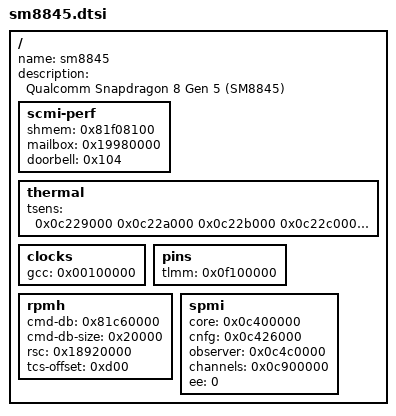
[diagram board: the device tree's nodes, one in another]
/dts-v1/;

// Shared SoC data for Snapdragon 8 Gen 5. Add register blocks with their backends.
/ {
	name = "sm8845";
	description = "Qualcomm Snapdragon 8 Gen 5 (SM8845)";

	// Channel used by the Ace 6T SM8845 reference port.
	scmi-perf {
		shmem = <0x81f08100>;
		mailbox = <0x19980000>;
		doorbell = <0x104>;
	};
	// TSENS v2, reg "tm" of tsens0..tsens6 in the Ace 6T's Android device tree (SROT at 0x0c222000..0x0c228000
	// is not needed: the hardware gives calibrated readings). Read only.
	thermal {
		tsens = <0x0c229000 0x0c22a000 0x0c22b000 0x0c22c000 0x0c22d000 0x0c22e000 0x0c22f000>;
	};

	// Ace 6T Android DT: clock-controller@100000; TLMM's per-pin registers start 1 MiB into its aperture.
	clocks {
		gcc = <0x00100000>;
	};
	pins {
		tlmm = <0x0f100000>;
	};
	// Android reserved-memory/aop_cmd_db_region and apps_rsc/ drv@2, channel@0.
	rpmh {
		cmd-db = <0x81c60000>;
		cmd-db-size = <0x20000>;
		rsc = <0x18920000>;
		tcs-offset = <0xd00>;
	};
	// Android arbiter@c400000 and spmi@c426000. The v8 map/owner layout needs a future shared
	// SPMI helper update: current helpers refuse it by version before any PMIC transfer.
	spmi {
		core = <0x0c400000>;
		cnfg = <0x0c426000>;
		observer = <0x0c4c0000>;
		channels = <0x0c900000>;
		ee = <0>;
	};
};
